AUTOSAR XML (schema 4-2-2)
package /ComponentTypes
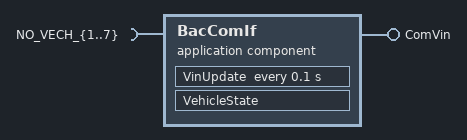
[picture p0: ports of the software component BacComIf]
  application sw component type BacComIf
    provide port ComVin: nonqueued-sender-com-spec=data-element=ComVin, provided-interface=ComVin
    7 x require port:
      NO_VECH_{1..7}: nonqueued-receiver-com-spec{data-element=NO_VECH_{1..7}, filter=data-filter-type=ALWAYS, init-value=[0]}, required-interface=NO_VECH_{1..7}
    behavior BacComIf_InternalBehavior
      timing event TMT_VinUpdate: start-on-event=VinUpdate, period=0.1
      port-api-options:
        enable-take-address=false, error-handling=NO-TRANSFORMER-ERROR-HANDLING, indirect-api=false, port=NO_VECH_{1..7}
      runnable VehicleState
      runnable VinUpdate
        data-receive-point-by-arguments:
          7 x access:
            REC_NO_VECH_{1..7}_NO_VECH_{1..7}: accessed-variable=NO_VECH_{1..7}.NO_VECH_{1..7}
        data-send-points:
          access SEND_ComVin_ComVin: accessed-variable=ComVin.ComVin
  swc implementation BacComIf_Implementation: behavior=BacComIf_InternalBehavior
    code-descriptors:
      code Default: artifact-descriptors=autosar-engineering-object={short-label=Default, category=SWSRC}
